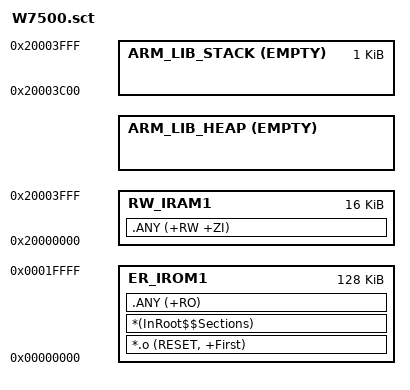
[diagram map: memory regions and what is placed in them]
#! armcc -E

#if !defined(MBED_BOOT_STACK_SIZE)
  #define MBED_BOOT_STACK_SIZE 0x400
#endif

#define Stack_Size MBED_BOOT_STACK_SIZE

; *************************************************************
; *** Scatter-Loading Description File generated by uVision ***
; *************************************************************

LR_IROM1 0x00000000 0x00020000  {    ; load region size_region
  ER_IROM1 0x00000000 0x00020000  {  ; load address = execution address
   *.o (RESET, +First)
   *(InRoot$$Sections)
   .ANY (+RO)
  }
  RW_IRAM1 0x20000000 0x00004000  {  ; RW data
   .ANY (+RW +ZI)
  }
  ARM_LIB_HEAP AlignExpr(+0, 16) EMPTY (0x20000000 + 0x00004000 - Stack_Size - AlignExpr(ImageLimit(RW_IRAM1), 16))  {
  }
  ARM_LIB_STACK (0x20000000+0x00004000) EMPTY -Stack_Size  { ; stack
  }
}

